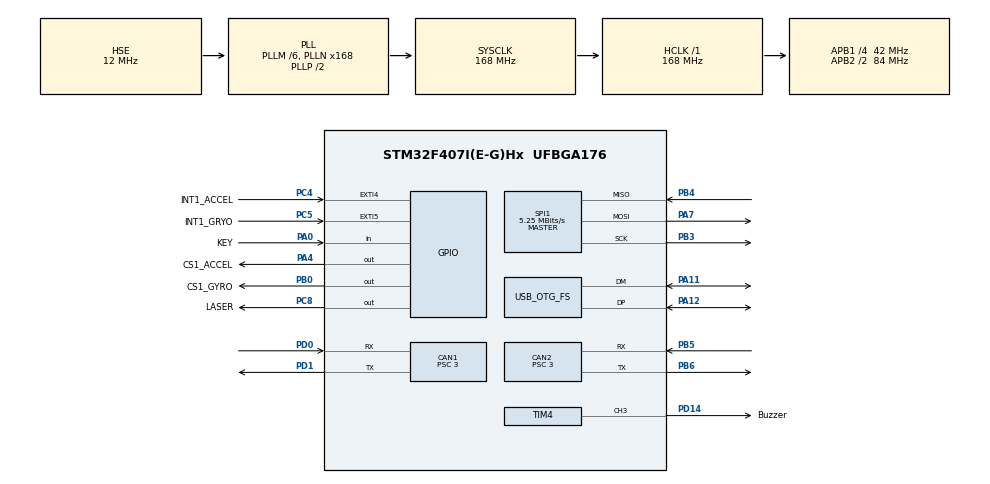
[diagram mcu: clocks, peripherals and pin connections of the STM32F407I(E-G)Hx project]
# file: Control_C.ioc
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CAN1.ABOM=ENABLE
CAN1.AWUM=ENABLE
CAN1.BS1=CAN_BS1_10TQ
CAN1.BS2=CAN_BS2_3TQ
CAN1.CalculateBaudRate=1000000
CAN1.CalculateTimeBit=1000
CAN1.CalculateTimeQuantum=71.42857142857143
CAN1.Prescaler=3
CAN1.TXFP=ENABLE
CAN2.ABOM=ENABLE
CAN2.AWUM=ENABLE
CAN2.BS1=CAN_BS1_10TQ
CAN2.BS2=CAN_BS2_3TQ
CAN2.CalculateBaudRate=1000000
CAN2.CalculateTimeBit=1000
CAN2.CalculateTimeQuantum=71.42857142857143
CAN2.Prescaler=3
CAN2.TXFP=ENABLE
Dma.Request0=SPI1_RX
Dma.Request1=SPI1_TX
Dma.SPI1_RX.0.Direction=DMA_PERIPH_TO_MEMORY
Dma.SPI1_RX.0.FIFOMode=DMA_FIFOMODE_DISABLE
Dma.SPI1_RX.0.Instance=DMA2_Stream0
Dma.SPI1_RX.0.MemDataAlignment=DMA_MDATAALIGN_BYTE
Dma.SPI1_RX.0.MemInc=DMA_MINC_ENABLE
Dma.SPI1_RX.0.Mode=DMA_NORMAL
Dma.SPI1_RX.0.PeriphDataAlignment=DMA_PDATAALIGN_BYTE
Dma.SPI1_RX.0.PeriphInc=DMA_PINC_DISABLE
Dma.SPI1_RX.0.Priority=DMA_PRIORITY_LOW
Dma.SPI1_TX.1.Direction=DMA_MEMORY_TO_PERIPH
Dma.SPI1_TX.1.FIFOMode=DMA_FIFOMODE_DISABLE
Dma.SPI1_TX.1.Instance=DMA2_Stream3
Dma.SPI1_TX.1.MemDataAlignment=DMA_MDATAALIGN_BYTE
Dma.SPI1_TX.1.MemInc=DMA_MINC_ENABLE
Dma.SPI1_TX.1.Mode=DMA_NORMAL
Dma.SPI1_TX.1.PeriphDataAlignment=DMA_PDATAALIGN_BYTE
Dma.SPI1_TX.1.PeriphInc=DMA_PINC_DISABLE
Dma.SPI1_TX.1.Priority=DMA_PRIORITY_LOW
FREERTOS.Tasks01=Monitor,-2,256,StartMonitorTask,As weak,NULL,Dynamic,NULL,NULL;Control,0,1024,StartControlTask,As external,NULL,Dynamic,NULL,NULL;System,2,128,StartSystemTask,As external,NULL,Dynamic,NULL,NULL
Mcu.Family=STM32F4
Mcu.Name=STM32F407I(E-G)Hx
Mcu.Package=UFBGA176
NVIC.CAN1_RX0_IRQn=true\:5\:0\:false\:false\:true\:true\:true\:true\:true
NVIC.CAN2_RX0_IRQn=true\:5\:0\:false\:false\:true\:true\:true\:true\:true
NVIC.DMA2_Stream0_IRQn=true\:5\:0\:false\:false\:true\:true\:false\:true\:true
NVIC.DMA2_Stream3_IRQn=true\:5\:0\:false\:false\:true\:true\:false\:true\:true
NVIC.OTG_FS_IRQn=true\:5\:0\:false\:false\:true\:true\:false\:true\:true
NVIC.PriorityGroup=NVIC_PRIORITYGROUP_4
NVIC.TIM2_IRQn=true\:15\:0\:false\:false\:true\:false\:false\:true\:true
NVIC.TimeBase=TIM2_IRQn
NVIC.TimeBaseIP=TIM2
PA0-WKUP.GPIO_Label=KEY
PA0-WKUP.GPIO_PuPd=GPIO_PULLUP
PA0-WKUP.Signal=GPIO_Input
PA11.Mode=Device_Only
PA11.Signal=USB_OTG_FS_DM
PA12.Mode=Device_Only
PA12.Signal=USB_OTG_FS_DP
PA13.Mode=Serial_Wire
PA13.Signal=SYS_JTMS-SWDIO
PA14.Mode=Serial_Wire
PA14.Signal=SYS_JTCK-SWCLK
PA4.GPIO_Label=CS1_ACCEL
PA4.GPIO_PuPd=GPIO_PULLUP
PA4.GPIO_Speed=GPIO_SPEED_FREQ_HIGH
PA4.PinState=GPIO_PIN_SET
PA4.Signal=GPIO_Output
PA7.Mode=Full_Duplex_Master
PA7.Signal=SPI1_MOSI
PB0.GPIO_Label=CS1_GYRO
PB0.GPIO_PuPd=GPIO_PULLUP
PB0.GPIO_Speed=GPIO_SPEED_FREQ_HIGH
PB0.PinState=GPIO_PIN_SET
PB0.Signal=GPIO_Output
PB3.Mode=Full_Duplex_Master
PB3.Signal=SPI1_SCK
PB4.Mode=Full_Duplex_Master
PB4.Signal=SPI1_MISO
PB5.Mode=CAN_Activate
PB5.Signal=CAN2_RX
PB6.Mode=CAN_Activate
PB6.Signal=CAN2_TX
PC4.GPIO_Label=INT1_ACCEL
PC4.GPIO_PuPd=GPIO_PULLUP
PC4.Signal=GPXTI4
PC5.GPIO_Label=INT1_GRYO
PC5.GPIO_PuPd=GPIO_PULLUP
PC5.Signal=GPXTI5
PC8.GPIO_Label=LASER
PC8.Signal=GPIO_Output
PD0.Mode=CAN_Activate
PD0.Signal=CAN1_RX
PD1.Mode=CAN_Activate
PD1.Signal=CAN1_TX
PD14.GPIO_Label=Buzzer
PD14.GPIO_Speed=GPIO_SPEED_FREQ_HIGH
PD14.Signal=S_TIM4_CH3
PH0-OSC_IN.Mode=HSE-External-Oscillator
PH0-OSC_IN.Signal=RCC_OSC_IN
PH1-OSC_OUT.Mode=HSE-External-Oscillator
PH1-OSC_OUT.Signal=RCC_OSC_OUT
ProjectManager.HeapSize=0x200
ProjectManager.StackSize=0x400
ProjectManager.TargetToolchain=MDK-ARM V5.32
RCC.48MHZClocksFreq_Value=48000000
RCC.AHBFreq_Value=168000000
RCC.APB1CLKDivider=RCC_HCLK_DIV4
RCC.APB1Freq_Value=42000000
RCC.APB1TimFreq_Value=84000000
RCC.APB2CLKDivider=RCC_HCLK_DIV2
RCC.APB2Freq_Value=84000000
RCC.APB2TimFreq_Value=168000000
RCC.CortexFreq_Value=168000000
RCC.HCLKFreq_Value=168000000
RCC.HSE_VALUE=12000000
RCC.HSI_VALUE=16000000
RCC.LSE_VALUE=32768
RCC.PLLM=6
RCC.PLLN=168
RCC.PLLQ=7
RCC.SYSCLKFreq_VALUE=168000000
RCC.SYSCLKSource=RCC_SYSCLKSOURCE_PLLCLK
RCC.VCOOutputFreq_Value=336000000
SH.S_TIM4_CH3.0=TIM4_CH3,PWM Generation3 CH3
SPI1.BaudRatePrescaler=SPI_BAUDRATEPRESCALER_16
SPI1.CLKPhase=SPI_PHASE_2EDGE
SPI1.CLKPolarity=SPI_POLARITY_HIGH
SPI1.CalculateBaudRate=5.25 MBits/s
SPI1.Direction=SPI_DIRECTION_2LINES
SPI1.Mode=SPI_MODE_MASTER
SPI1.VirtualType=VM_MASTER
TIM4.AutoReloadPreload=TIM_AUTORELOAD_PRELOAD_ENABLE
TIM4.Channel-PWM\ Generation3\ CH3=TIM_CHANNEL_3
TIM4.Period=1000-1
TIM4.Pulse-PWM\ Generation3\ CH3=500
USB_DEVICE.CLASS_NAME_FS=CDC
USB_DEVICE.VirtualMode-CDC_FS=Cdc
USB_DEVICE.VirtualModeFS=Cdc_FS
USB_OTG_FS.VirtualMode=Device_Only
VP_FREERTOS_VS_CMSIS_V1.Mode=CMSIS_V1
VP_IWDG_VS_IWDG.Mode=IWDG_Activate
VP_SYS_VS_tim2.Mode=TIM2
VP_TIM4_VS_ClockSourceINT.Mode=Internal
VP_USB_DEVICE_VS_USB_DEVICE_CDC_FS.Mode=CDC_FS
board=custom

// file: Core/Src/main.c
/* USER CODE BEGIN Header */
/**
  ******************************************************************************
  * @file           : main.c
  * @brief          : Main program body
  ******************************************************************************
  * @attention
  *
  * Copyright (c) 2025 STMicroelectronics.
  * All rights reserved.
  *
  * This software is licensed under terms that can be found in the LICENSE file
  * in the root directory of this software component.
  * If no LICENSE file comes with this software, it is provided AS-IS.
  *
  ******************************************************************************
  */
/* USER CODE END Header */
#include "main.h"
#include "cmsis_os.h"
#include "can.h"
#include "dma.h"
#include "iwdg.h"
#include "spi.h"
#include "tim.h"
#include "usb_device.h"
#include "gpio.h"

/* USER CODE BEGIN Includes */
#include "driver.h"
#include "device.h"
/* USER CODE END Includes */

void SystemClock_Config(void);
void MX_FREERTOS_Init(void);

int main(void)
{

  /* MCU Configuration--------------------------------------------------------*/

  /* Reset of all peripherals, Initializes the Flash interface and the Systick. */
  HAL_Init();

  /* Configure the system clock */
  SystemClock_Config();

  /* Initialize all configured peripherals */
  MX_GPIO_Init();
  MX_DMA_Init();
  MX_CAN1_Init();
  MX_CAN2_Init();
//  MX_IWDG_Init();
  MX_SPI1_Init();
  MX_TIM4_Init();
  /* USER CODE BEGIN 2 */
	MX_USB_DEVICE_Init();
	Device_Init();
	Driver_Init();

  /* USER CODE END 2 */

  /* Call init function for freertos objects (in cmsis_os2.c) */
  MX_FREERTOS_Init();

  /* Start scheduler */
  osKernelStart();

  /* We should never get here as control is now taken by the scheduler */

  /* Infinite loop */
  while (1)
  {

  }
}

void SystemClock_Config(void)
{
  RCC_OscInitTypeDef RCC_OscInitStruct = {0};
  RCC_ClkInitTypeDef RCC_ClkInitStruct = {0};

  /** Configure the main internal regulator output voltage
  */
  __HAL_RCC_PWR_CLK_ENABLE();
  __HAL_PWR_VOLTAGESCALING_CONFIG(PWR_REGULATOR_VOLTAGE_SCALE1);

  /** Initializes the RCC Oscillators according to the specified parameters
  * in the RCC_OscInitTypeDef structure.
  */
  RCC_OscInitStruct.OscillatorType = RCC_OSCILLATORTYPE_LSI|RCC_OSCILLATORTYPE_HSE;
  RCC_OscInitStruct.HSEState = RCC_HSE_ON;
  RCC_OscInitStruct.LSIState = RCC_LSI_ON;
  RCC_OscInitStruct.PLL.PLLState = RCC_PLL_ON;
  RCC_OscInitStruct.PLL.PLLSource = RCC_PLLSOURCE_HSE;
  RCC_OscInitStruct.PLL.PLLM = 6;
  RCC_OscInitStruct.PLL.PLLN = 168;
  RCC_OscInitStruct.PLL.PLLP = RCC_PLLP_DIV2;
  RCC_OscInitStruct.PLL.PLLQ = 7;
  if (HAL_RCC_OscConfig(&RCC_OscInitStruct) != HAL_OK)
  {
    Error_Handler();
  }

  /** Initializes the CPU, AHB and APB buses clocks
  */
  RCC_ClkInitStruct.ClockType = RCC_CLOCKTYPE_HCLK|RCC_CLOCKTYPE_SYSCLK
                              |RCC_CLOCKTYPE_PCLK1|RCC_CLOCKTYPE_PCLK2;
  RCC_ClkInitStruct.SYSCLKSource = RCC_SYSCLKSOURCE_PLLCLK;
  RCC_ClkInitStruct.AHBCLKDivider = RCC_SYSCLK_DIV1;
  RCC_ClkInitStruct.APB1CLKDivider = RCC_HCLK_DIV4;
  RCC_ClkInitStruct.APB2CLKDivider = RCC_HCLK_DIV2;

  if (HAL_RCC_ClockConfig(&RCC_ClkInitStruct, FLASH_LATENCY_5) != HAL_OK)
  {
    Error_Handler();
  }
}

void HAL_TIM_PeriodElapsedCallback(TIM_HandleTypeDef *htim)
{
  if (htim->Instance == TIM2)
  {
    HAL_IncTick();
  }
}

void Error_Handler(void)
{
  __disable_irq();
  while (1)
  {
  }
}

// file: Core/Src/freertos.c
/* USER CODE BEGIN Header */
/**
  ******************************************************************************
  * File Name          : freertos.c
  * Description        : Code for freertos applications
  ******************************************************************************
  * @attention
  *
  * Copyright (c) 2025 STMicroelectronics.
  * All rights reserved.
  *
  * This software is licensed under terms that can be found in the LICENSE file
  * in the root directory of this software component.
  * If no LICENSE file comes with this software, it is provided AS-IS.
  *
  ******************************************************************************
  */
/* USER CODE END Header */

#include "FreeRTOS.h"
#include "task.h"
#include "main.h"
#include "cmsis_os.h"

osThreadId MonitorHandle;
osThreadId ControlHandle;
osThreadId SystemHandle;

void StartMonitorTask(void const * argument);
extern void StartControlTask(void const * argument);
extern void StartSystemTask(void const * argument);

extern void MX_USB_DEVICE_Init(void);
void MX_FREERTOS_Init(void); /* (MISRA C 2004 rule 8.1) */

/* GetIdleTaskMemory prototype (linked to static allocation support) */
void vApplicationGetIdleTaskMemory( StaticTask_t **ppxIdleTaskTCBBuffer, StackType_t **ppxIdleTaskStackBuffer, uint32_t *pulIdleTaskStackSize );

/* USER CODE BEGIN GET_IDLE_TASK_MEMORY */
static StaticTask_t xIdleTaskTCBBuffer;
static StackType_t xIdleStack[configMINIMAL_STACK_SIZE];

void vApplicationGetIdleTaskMemory( StaticTask_t **ppxIdleTaskTCBBuffer, StackType_t **ppxIdleTaskStackBuffer, uint32_t *pulIdleTaskStackSize )
{
  *ppxIdleTaskTCBBuffer = &xIdleTaskTCBBuffer;
  *ppxIdleTaskStackBuffer = &xIdleStack[0];
  *pulIdleTaskStackSize = configMINIMAL_STACK_SIZE;
  /* place for user code */
}
/* USER CODE END GET_IDLE_TASK_MEMORY */

void MX_FREERTOS_Init(void) {

  /* Create the thread(s) */
  /* definition and creation of Monitor */
  osThreadDef(Monitor, StartMonitorTask, osPriorityLow, 0, 256);
  MonitorHandle = osThreadCreate(osThread(Monitor), NULL);

  /* definition and creation of Control */
  osThreadDef(Control, StartControlTask, osPriorityNormal, 0, 1024);
  ControlHandle = osThreadCreate(osThread(Control), NULL);

  /* definition and creation of System */
  osThreadDef(System, StartSystemTask, osPriorityHigh, 0, 128);
  SystemHandle = osThreadCreate(osThread(System), NULL);

}

__weak void StartMonitorTask(void const * argument)
{
  /* init code for USB_DEVICE */
  MX_USB_DEVICE_Init();
  for(;;)
  {
    osDelay(1);
  }
}
